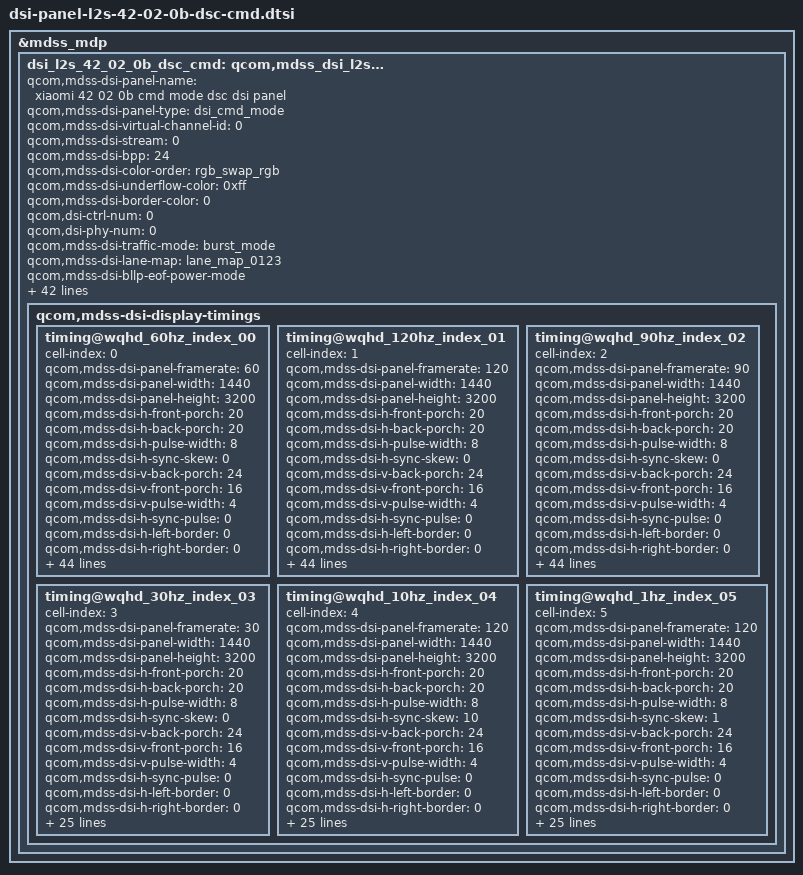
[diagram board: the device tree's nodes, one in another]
&mdss_mdp {
	dsi_l2s_42_02_0b_dsc_cmd: qcom,mdss_dsi_l2s_42_02_0b_dsc_cmd {
		qcom,mdss-dsi-panel-name = "xiaomi 42 02 0b cmd mode dsc dsi panel";
		qcom,mdss-dsi-panel-type = "dsi_cmd_mode";
		qcom,mdss-dsi-virtual-channel-id = <0>;
		qcom,mdss-dsi-stream = <0>;
		qcom,mdss-dsi-bpp = <24>;
		qcom,mdss-dsi-color-order = "rgb_swap_rgb";
		qcom,mdss-dsi-underflow-color = <0xff>;
		qcom,mdss-dsi-border-color = <0>;
		qcom,dsi-ctrl-num = <0>;
		qcom,dsi-phy-num = <0>;

		qcom,mdss-dsi-traffic-mode = "burst_mode";
		qcom,mdss-dsi-lane-map = "lane_map_0123";
		qcom,mdss-dsi-bllp-eof-power-mode;
		qcom,mdss-dsi-bllp-power-mode;
		qcom,mdss-dsi-lane-0-state;
		qcom,mdss-dsi-lane-1-state;
		qcom,mdss-dsi-lane-2-state;
		qcom,mdss-dsi-lane-3-state;
		qcom,mdss-dsi-dma-trigger = "trigger_sw";
		qcom,mdss-dsi-mdp-trigger = "none";
		qcom,mdss-dsi-reset-sequence = <0 10>, <1 10>;
		qcom,mdss-pan-physical-width-dimension = <701>;
		qcom,mdss-pan-physical-height-dimension = <1558>;
		qcom,mdss-dsi-te-pin-select = <1>;
		qcom,mdss-dsi-wr-mem-start = <0x2c>;
		qcom,mdss-dsi-wr-mem-continue = <0x3c>;
		qcom,mdss-dsi-te-dcs-command = <1>;
		qcom,mdss-dsi-te-check-enable;
		qcom,mdss-dsi-te-using-te-pin;
		qcom,mdss-dsi-tx-eot-append;
		qcom,mdss-dsi-lp11-init;

		qcom,mdss-dsi-bl-inverted-dbv;
		qcom,mdss-dsi-panel-dimming-enabled;
		qcom,bl-update-flag = "delay_until_first_frame";

		qcom,mdss-dsi-panel-hdr-enabled;
		qcom,mdss-dsi-panel-hdr-color-primaries = <14500 15500 32000
			17000 15500 30000 8000 3000>;
		qcom,mdss-dsi-panel-peak-brightness = <4200000>;
		qcom,mdss-dsi-panel-blackness-level = <3230>;

		qcom,mdss-dsi-dma-schedule-line = <1>;
		qcom,mdss-dsi-dma-schedule-window = <50>;

		/* IRQF_ONESHOT | IRQF_TRIGGER_HIGH */
		mi,esd-err-irq-gpio = <&tlmm 116 0x2004>;
		mi,panel-id = <0x004C3253 0x00420200>;

		mi,local-hbm-enabled;
		mi,local-hbm-alpha-ctrl-aa-area;

		mi,local-hbm-ui-ready-delay-num-frame = <4>; /* 4 frame */
		mi,fod-low-brightness-clone-threshold = <411>;
		mi,fod-low-brightness-lux-threshold = <1>;
		mi,need-fod-animal-in-normal-enabled;

		mi,panel-on-dimming-delay = <120>;
		mi,max-brightness-clone = <8191>;
		mi,normal-max-brightness-clone = <8191>;
		mi,thermal-dimming-flag;

		mi,doze-hbm-dbv-level = <229>;
		mi,doze-lbm-dbv-level = <16>;

		qcom,mdss-dsi-display-timings {
			timing@wqhd_60hz_index_00 {
				#include "dsi-panel-l2s-42-02-0b-dsc-cmd-common.dtsi"
				cell-index = <0>;
				qcom,mdss-dsi-panel-framerate = <60>;
				qcom,mdss-dsi-panel-width = <1440>;
				qcom,mdss-dsi-panel-height = <3200>;
				qcom,mdss-dsi-h-front-porch = <20>;
				qcom,mdss-dsi-h-back-porch = <20>;
				qcom,mdss-dsi-h-pulse-width = <8>;
				qcom,mdss-dsi-h-sync-skew = <0>;
				qcom,mdss-dsi-v-back-porch = <24>;
				qcom,mdss-dsi-v-front-porch = <16>;
				qcom,mdss-dsi-v-pulse-width = <4>;
				qcom,mdss-dsi-h-sync-pulse = <0>;
				qcom,mdss-dsi-h-left-border = <0>;
				qcom,mdss-dsi-h-right-border = <0>;
				qcom,mdss-dsi-v-top-border = <0>;
				qcom,mdss-dsi-v-bottom-border = <0>;
				qcom,mdss-dsi-panel-clockrate = <1240000000>;
				qcom,mdss-dsi-panel-jitter = <0x5 0x1>;
				qcom,mdss-mdp-transfer-time-us = <7300>;

				/* the cmd sequence sync TE */
				mi,mdss-dsi-exit-90fps-timing-switch-command = [
					39 00 00 40 00 00 02 5A 01
					39 00 00 40 00 00 06 F0 55 AA 52 08 00
					39 00 00 40 00 00 02 6F 1C
					39 00 00 40 00 00 09 BA 91 01 01 00 01 01 01 00
					39 00 00 40 00 00 02 BA 00
					39 00 00 00 00 00 02 2F 30
				];
				mi,mdss-dsi-exit-90fps-timing-switch-command-state = "dsi_hs_mode";

				qcom,mdss-dsi-timing-switch-command = [
					39 00 00 40 00 00 02 5A 01
					39 00 00 40 00 00 06 F0 55 AA 52 08 00
					39 00 00 40 00 00 02 6F 1C
					39 00 00 40 00 00 09 BA 91 01 01 00 01 01 01 00
					39 00 00 40 00 00 02 BA 00
					39 00 00 00 00 00 02 2F 30
				];
				qcom,mdss-dsi-timing-switch-command-state = "dsi_hs_mode";

				qcom,mdss-dsi-on-command = [
					/*DVDD strong*/
					39 00 00 40 00 00 06 F0 55 AA 52 08 01
					39 00 00 40 00 00 02 6F 01
					39 00 00 00 00 00 04 C5 0B 0B 0B
					/* source rising failing time */
					39 00 00 40 00 00 05 FF AA 55 A5 80
					39 00 00 40 00 00 02 6F 1B
					39 00 00 00 00 00 02 F4 55
					/* DSC setting */
					39 00 00 40 00 00 03 90 03 03
					39 00 00 00 00 00 13 91
					        89 28 00 28 D2 00 02 86 04 3A 00 0A 02 AB 01 E9
					        10 F0
					/* CASET/RASET */
					39 00 00 40 00 00 05 2A 00 00 05 9F
					39 00 00 00 00 00 05 2B 00 00 0C 7F
					/* TE ON */
					39 00 00 40 00 00 02 35 00
					39 00 00 40 00 00 05 3B 00 18 00 10
					39 00 00 00 00 00 02 5A 01
					/* BACKLIGHT ON */
					//DBV
					39 00 00 40 00 00 02 53 20
					39 00 00 40 00 00 07 51 00 00 00 00 00 00
					39 00 00 00 00 00 02 9C 01
					/*GIR OFF*/
					39 00 00 00 00 00 02 5F 01
					/* 60 Hz */
					39 00 00 40 00 00 02 5A 01
					39 00 00 40 00 00 06 F0 55 AA 52 08 00
					39 00 00 40 00 00 02 6F 1C
					39 00 00 40 00 00 09 BA 91 01 01 00 01 01 01 00
					39 00 00 40 00 00 02 BA 00
					39 00 00 00 00 00 02 2F 30
					/* round off */
					39 00 00 40 00 00 06 F0 55 AA 52 08 07
					39 00 00 00 00 00 02 C0 B0
					/*ESD Error flag  Active high*/
					39 00 00 40 00 00 06 F0 55 AA 52 08 00
					39 00 00 40 00 00 05 BE 47 CF 4C 4B
					39 00 00 40 00 00 02 6F 09
					39 00 00 00 00 00 02 BE 2A
					/*TP Hsync*/
					39 00 00 40 00 00 06 F0 55 AA 52 08 01
					39 00 00 00 00 00 07 D1 07 02 0C 00 00 0F
					/*spped flash reload*/
					//39 00 00 40 00 00 06 F0 55 AA 52 08 04
					//39 00 00 00 00 00 02 C2 12
					/* Sleep Out */
					05 00 00 00 78 00 01 11
					/*black mask off*/
					39 00 00 00 00 00 02 9B 00
					/* Display On */
					05 00 00 00 00 00 01 29
				];
				qcom,mdss-dsi-on-command-state = "dsi_lp_mode";

				mi,mdss-dsi-flat-mode-on-command = [
					39 00 00 40 00 00 02 2F 32
					39 00 00 00 00 00 02 5F 00
				];
				mi,mdss-dsi-flat-mode-on-command-state = "dsi_lp_mode";

				mi,mdss-dsi-flat-mode-off-command = [
					39 00 00 00 00 00 02 5F 01
				];
				mi,mdss-dsi-flat-mode-off-command-state = "dsi_lp_mode";

				qcom,mdss-dsi-nolp-command = [
					39 00 00 40 00 00 02 65 00
					39 00 00 40 00 00 02 38 00
					/*60HZ*/
					39 00 00 40 00 00 02 5A 01
					39 00 00 40 00 00 06 F0 55 AA 52 08 00
					39 00 00 40 00 00 02 6F 1C
					39 00 00 40 00 00 09 BA 91 01 01 00 01 01 01 00
					39 00 00 40 00 00 02 BA 00
					39 00 00 00 00 00 02 2F 30
				];
				qcom,mdss-dsi-nolp-command-state = "dsi_lp_mode";

				mi,mdss-dsi-doze-hbm-nolp-command = [
					39 00 00 40 00 00 02 65 00
					39 00 00 40 00 00 02 38 00
					/*60HZ*/
					39 00 00 40 00 00 02 5A 01
					39 00 00 40 00 00 06 F0 55 AA 52 08 00
					39 00 00 40 00 00 02 6F 1C
					39 00 00 40 00 00 09 BA 91 01 01 00 01 01 01 00
					39 00 00 40 00 00 02 BA 00
					39 00 00 00 00 00 02 2F 30
				];
				mi,mdss-dsi-doze-hbm-nolp-command-state = "dsi_lp_mode";

				mi,mdss-dsi-doze-lbm-nolp-command = [
					39 00 00 40 00 00 02 65 00
					39 00 00 40 00 00 02 38 00
					/*60HZ*/
					39 00 00 40 00 00 02 5A 01
					39 00 00 40 00 00 06 F0 55 AA 52 08 00
					39 00 00 40 00 00 02 6F 1C
					39 00 00 40 00 00 09 BA 91 01 01 00 01 01 01 00
					39 00 00 40 00 00 02 BA 00
					39 00 00 00 00 00 02 2F 30
				];
				mi,mdss-dsi-doze-lbm-nolp-command-state = "dsi_lp_mode";

				qcom,compression-mode = "dsc";
				qcom,mdss-dsc-version = <0x11>;
				qcom,mdss-dsc-scr-version = <0x0>;
				qcom,mdss-dsc-slice-height = <40>;
				qcom,mdss-dsc-slice-width = <720>;
				qcom,mdss-dsc-slice-per-pkt = <2>;
				qcom,mdss-dsc-bit-per-component = <8>;
				qcom,mdss-dsc-bit-per-pixel = <8>;
				qcom,mdss-dsc-block-prediction-enable;
			};

			timing@wqhd_120hz_index_01 {
				#include "dsi-panel-l2s-42-02-0b-dsc-cmd-common.dtsi"
				cell-index = <1>;
				qcom,mdss-dsi-panel-framerate = <120>;
				qcom,mdss-dsi-panel-width = <1440>;
				qcom,mdss-dsi-panel-height = <3200>;
				qcom,mdss-dsi-h-front-porch = <20>;
				qcom,mdss-dsi-h-back-porch = <20>;
				qcom,mdss-dsi-h-pulse-width = <8>;
				qcom,mdss-dsi-h-sync-skew = <0>;
				qcom,mdss-dsi-v-back-porch = <24>;
				qcom,mdss-dsi-v-front-porch = <16>;
				qcom,mdss-dsi-v-pulse-width = <4>;
				qcom,mdss-dsi-h-sync-pulse = <0>;
				qcom,mdss-dsi-h-left-border = <0>;
				qcom,mdss-dsi-h-right-border = <0>;
				qcom,mdss-dsi-v-top-border = <0>;
				qcom,mdss-dsi-v-bottom-border = <0>;
				qcom,mdss-dsi-panel-clockrate = <1240000000>;
				qcom,mdss-dsi-panel-jitter = <0x5 0x1>;
				qcom,mdss-mdp-transfer-time-us = <7300>;

				/* the cmd sequence sync TE */
				mi,mdss-dsi-exit-90fps-timing-switch-command = [
					39 00 00 00 00 00 02 2F 00
				];
				mi,mdss-dsi-exit-90fps-timing-switch-command-state = "dsi_hs_mode";

				qcom,mdss-dsi-timing-switch-command = [
					39 00 00 00 00 00 02 2F 00
				];
				qcom,mdss-dsi-timing-switch-command-state = "dsi_hs_mode";

				qcom,mdss-dsi-on-command = [
					/*DVDD strong*/
					39 00 00 40 00 00 06 F0 55 AA 52 08 01
					39 00 00 40 00 00 02 6F 01
					39 00 00 00 00 00 04 C5 0B 0B 0B
					/* source rising failing time */
					39 00 00 40 00 00 05 FF AA 55 A5 80
					39 00 00 40 00 00 02 6F 1B
					39 00 00 00 00 00 02 F4 55
					/* DSC setting */
					39 00 00 40 00 00 03 90 03 03
					39 00 00 00 00 00 13 91
					        89 28 00 28 D2 00 02 86 04 3A 00 0A 02 AB 01 E9
					        10 F0
					/* CASET/RASET */
					39 00 00 40 00 00 05 2A 00 00 05 9F
					39 00 00 00 00 00 05 2B 00 00 0C 7F
					/* TE ON */
					39 00 00 40 00 00 02 35 00
					39 00 00 40 00 00 05 3B 00 18 00 10
					39 00 00 00 00 00 02 5A 01
					/* BACKLIGHT ON */
					//DBV
					39 00 00 40 00 00 02 53 20
					39 00 00 40 00 00 07 51 00 00 00 00 00 00
					39 00 00 00 00 00 02 9C 01
					/*GIR OFF*/
					39 00 00 00 00 00 02 5F 01
					/* 120 Hz */
					39 00 00 40 00 00 02 2F 00
					39 00 00 00 00 00 02 26 00
					/* round off */
					39 00 00 00 00 00 06 F0 55 AA 52 08 07
					39 00 00 00 00 00 02 C0 B0
					/*ESD Error flag  Active high*/
					39 00 00 40 00 00 06 F0 55 AA 52 08 00
					39 00 00 40 00 00 05 BE 47 CF 4C 4B
					39 00 00 40 00 00 02 6F 09
					39 00 00 00 00 00 02 BE 2A
					/*TP Hsync*/
					39 00 00 40 00 00 06 F0 55 AA 52 08 01
					39 00 00 00 00 00 07 D1 07 02 0C 00 00 0F
					/* Sleep Out */
					05 00 00 00 78 00 01 11
					/* Display On */
					05 00 00 00 00 00 01 29
				];
				qcom,mdss-dsi-on-command-state = "dsi_lp_mode";

				mi,mdss-dsi-flat-mode-on-command = [
					39 00 00 00 00 00 02 2F 02
				];
				mi,mdss-dsi-flat-mode-on-command-state = "dsi_lp_mode";

				mi,mdss-dsi-flat-mode-off-command = [
					39 00 00 40 00 00 02 2F 00
					39 00 00 00 00 00 02 26 00
				];
				mi,mdss-dsi-flat-mode-off-command-state = "dsi_lp_mode";

				qcom,mdss-dsi-nolp-command = [
					39 00 00 40 00 00 02 65 00
					39 00 00 40 00 00 02 38 00
					/*120HZ*/
					39 00 00 00 00 00 02 2F 00
				];
				qcom,mdss-dsi-nolp-command-state = "dsi_lp_mode";

				mi,mdss-dsi-doze-hbm-nolp-command = [
					39 00 00 40 00 00 02 65 00
					39 00 00 40 00 00 02 38 00
					/*120HZ*/
					39 00 00 00 00 00 02 2F 00
				];
				mi,mdss-dsi-doze-hbm-nolp-command-state = "dsi_lp_mode";

				mi,mdss-dsi-doze-lbm-nolp-command = [
					39 00 00 40 00 00 02 65 00
					39 00 00 40 00 00 02 38 00
					/*120HZ*/
					39 00 00 00 00 00 02 2F 00
				];
				mi,mdss-dsi-doze-lbm-nolp-command-state = "dsi_lp_mode";

				qcom,compression-mode = "dsc";
				qcom,mdss-dsc-version = <0x11>;
				qcom,mdss-dsc-scr-version = <0x0>;
				qcom,mdss-dsc-slice-height = <40>;
				qcom,mdss-dsc-slice-width = <720>;
				qcom,mdss-dsc-slice-per-pkt = <2>;
				qcom,mdss-dsc-bit-per-component = <8>;
				qcom,mdss-dsc-bit-per-pixel = <8>;
				qcom,mdss-dsc-block-prediction-enable;
			};

			timing@wqhd_90hz_index_02 {
				#include "dsi-panel-l2s-42-02-0b-dsc-cmd-common.dtsi"
				cell-index = <2>;
				qcom,mdss-dsi-panel-framerate = <90>;
				qcom,mdss-dsi-panel-width = <1440>;
				qcom,mdss-dsi-panel-height = <3200>;
				qcom,mdss-dsi-h-front-porch = <20>;
				qcom,mdss-dsi-h-back-porch = <20>;
				qcom,mdss-dsi-h-pulse-width = <8>;
				qcom,mdss-dsi-h-sync-skew = <0>;
				qcom,mdss-dsi-v-back-porch = <24>;
				qcom,mdss-dsi-v-front-porch = <16>;
				qcom,mdss-dsi-v-pulse-width = <4>;
				qcom,mdss-dsi-h-sync-pulse = <0>;
				qcom,mdss-dsi-h-left-border = <0>;
				qcom,mdss-dsi-h-right-border = <0>;
				qcom,mdss-dsi-v-top-border = <0>;
				qcom,mdss-dsi-v-bottom-border = <0>;
				qcom,mdss-dsi-panel-clockrate = <1240000000>;
				qcom,mdss-dsi-panel-jitter = <0x5 0x1>;
				qcom,mdss-mdp-transfer-time-us = <7300>;

				mi,mdss-dsi-exit-90fps-timing-switch-command = [
					39 00 00 00 00 00 02 2F 01
				];
				mi,mdss-dsi-exit-90fps-timing-switch-command-state = "dsi_hs_mode";

				qcom,mdss-dsi-timing-switch-command = [
					39 00 00 00 00 00 02 2F 01
				];
				qcom,mdss-dsi-timing-switch-command-state = "dsi_hs_mode";

				qcom,mdss-dsi-on-command = [
					/*DVDD strong*/
					39 00 00 40 00 00 06 F0 55 AA 52 08 01
					39 00 00 40 00 00 02 6F 01
					39 00 00 00 00 00 04 C5 0B 0B 0B
					/* source rising failing time */
					39 00 00 40 00 00 05 FF AA 55 A5 80
					39 00 00 40 00 00 02 6F 1B
					39 00 00 00 00 00 02 F4 55
					/* DSC setting */
					39 00 00 40 00 00 03 90 03 03
					39 00 00 00 00 00 13 91
						89 28 00 28 D2 00 02 86 04 3A 00 0A 02 AB 01 E9
						10 F0
					/* CASET/RASET */
					39 00 00 40 00 00 05 2A 00 00 05 9F
					39 00 00 00 00 00 05 2B 00 00 0C 7F
					/* TE ON */
					39 00 00 40 00 00 02 35 00
					39 00 00 40 00 00 05 3B 00 18 00 10
					39 00 00 00 00 00 02 5A 01
					//DBV
					39 00 00 40 00 00 02 53 20
					39 00 00 40 00 00 07 51 00 00 00 00 00 00
					39 00 00 00 00 00 02 9C 01
					/*GIR OFF*/
					39 00 00 00 00 00 02 5F 01
					/* 90 Hz */
					39 00 00 00 00 00 02 2F 01
					/* round off */
					39 00 00 40 00 00 06 F0 55 AA 52 08 07
					39 00 00 00 00 00 02 C0 B0
					/*ESD Error flag  Active high*/
					39 00 00 40 00 00 06 F0 55 AA 52 08 00
					39 00 00 40 00 00 05 BE 47 CF 4C 4B
					39 00 00 40 00 00 02 6F 09
					39 00 00 00 00 00 02 BE 2A
					/*TP Hsync*/
					39 00 00 40 00 00 06 F0 55 AA 52 08 01
					39 00 00 00 00 00 07 D1 07 02 0C 00 00 0F
					/* Sleep Out */
					05 00 00 00 78 00 01 11
					/* Display On */
					05 00 00 00 00 00 01 29
				];
				qcom,mdss-dsi-on-command-state = "dsi_lp_mode";

				mi,mdss-dsi-flat-mode-on-command = [
					39 00 00 00 00 00 02 2F 03
				];
				mi,mdss-dsi-flat-mode-on-command-state = "dsi_lp_mode";

				mi,mdss-dsi-flat-mode-off-command = [
					39 00 00 00 00 00 02 2F 01
				];
                                mi,mdss-dsi-flat-mode-off-command-state = "dsi_lp_mode";

				qcom,mdss-dsi-nolp-command = [
					39 00 00 40 00 00 02 65 00
					39 00 00 40 00 00 02 38 00
					/*90HZ*/
					39 00 00 00 00 00 02 2F 01
				];
				qcom,mdss-dsi-nolp-command-state = "dsi_lp_mode";

				mi,mdss-dsi-doze-hbm-nolp-command = [
					39 00 00 40 00 00 03 51 07 FF
					39 00 00 40 00 00 02 65 00
					39 00 00 40 00 00 02 38 00
					/*90HZ*/
					39 00 00 00 00 00 02 2F 01
				];
				mi,mdss-dsi-doze-hbm-nolp-command-state = "dsi_lp_mode";

				mi,mdss-dsi-doze-lbm-nolp-command = [
					39 00 00 40 00 00 03 51 07 FF
					39 00 00 40 00 00 02 65 00
					39 00 00 40 00 00 02 38 00
					/*90HZ*/
					39 00 00 00 00 00 02 2F 01
				];
				mi,mdss-dsi-doze-lbm-nolp-command-state = "dsi_lp_mode";

				qcom,compression-mode = "dsc";
				qcom,mdss-dsc-version = <0x11>;
				qcom,mdss-dsc-scr-version = <0x0>;
				qcom,mdss-dsc-slice-height = <40>;
				qcom,mdss-dsc-slice-width = <720>;
				qcom,mdss-dsc-slice-per-pkt = <2>;
				qcom,mdss-dsc-bit-per-component = <8>;
				qcom,mdss-dsc-bit-per-pixel = <8>;
				qcom,mdss-dsc-block-prediction-enable;
			};

			timing@wqhd_30hz_index_03 {
				#include "dsi-panel-l2s-42-02-0b-dsc-cmd-common.dtsi"
				cell-index = <3>;
				qcom,mdss-dsi-panel-framerate = <30>;
				qcom,mdss-dsi-panel-width = <1440>;
				qcom,mdss-dsi-panel-height = <3200>;
				qcom,mdss-dsi-h-front-porch = <20>;
				qcom,mdss-dsi-h-back-porch = <20>;
				qcom,mdss-dsi-h-pulse-width = <8>;
				qcom,mdss-dsi-h-sync-skew = <0>;
				qcom,mdss-dsi-v-back-porch = <24>;
				qcom,mdss-dsi-v-front-porch = <16>;
				qcom,mdss-dsi-v-pulse-width = <4>;
				qcom,mdss-dsi-h-sync-pulse = <0>;
				qcom,mdss-dsi-h-left-border = <0>;
				qcom,mdss-dsi-h-right-border = <0>;
				qcom,mdss-dsi-v-top-border = <0>;
				qcom,mdss-dsi-v-bottom-border = <0>;
				qcom,mdss-dsi-panel-clockrate = <1240000000>;
				qcom,mdss-dsi-panel-jitter = <0x5 0x1>;
				qcom,mdss-mdp-transfer-time-us = <7300>;

				/* the cmd sequence sync TE */
				mi,mdss-dsi-exit-90fps-timing-switch-command = [
					39 00 00 40 00 00 02 5A 01
					39 00 00 40 00 00 06 F0 55 AA 52 08 00
					39 00 00 40 00 00 02 6F 1C
					39 00 00 40 00 00 09 BA 91 03 03 00 01 03 03 00
					39 00 00 40 00 00 02 BA 00
					39 00 00 00 00 00 02 2F 30
				];
				mi,mdss-dsi-exit-90fps-timing-switch-command-state = "dsi_hs_mode";

				qcom,mdss-dsi-timing-switch-command = [
					39 00 00 40 00 00 02 5A 01
					39 00 00 40 00 00 06 F0 55 AA 52 08 00
					39 00 00 40 00 00 02 6F 1C
					39 00 00 40 00 00 09 BA 91 03 03 00 01 03 03 00
					39 00 00 40 00 00 02 BA 00
					39 00 00 00 00 00 02 2F 30
				];
				qcom,mdss-dsi-timing-switch-command-state = "dsi_hs_mode";

				qcom,mdss-dsi-on-command = [
					/*DVDD strong*/
					39 00 00 40 00 00 06 F0 55 AA 52 08 01
					39 00 00 40 00 00 02 6F 01
					39 00 00 00 00 00 04 C5 0B 0B 0B
					/* source rising failing time */
					39 00 00 40 00 00 05 FF AA 55 A5 80
					39 00 00 40 00 00 02 6F 1B
					39 00 00 00 00 00 02 F4 55
					/* DSC setting */
					39 00 00 40 00 00 03 90 03 03
					39 00 00 00 00 00 13 91
					        89 28 00 28 D2 00 02 86 04 3A 00 0A 02 AB 01 E9
					        10 F0
					/* CASET/RASET */
					39 00 00 40 00 00 05 2A 00 00 05 9F
					39 00 00 00 00 00 05 2B 00 00 0C 7F
					/* TE ON */
					39 00 00 40 00 00 02 35 00
					39 00 00 40 00 00 05 3B 00 18 00 10
					39 00 00 00 00 00 02 5A 01
					/* BACKLIGHT ON */
					//DBV
					39 00 00 40 00 00 02 53 20
					39 00 00 40 00 00 07 51 00 00 00 00 00 00
					39 00 00 00 00 00 02 9C 01
					/*GIR OFF*/
					39 00 00 00 00 00 02 5F 01
					/* 30 Hz */
					39 00 00 40 00 00 02 5A 01
					39 00 00 40 00 00 06 F0 55 AA 52 08 00
					39 00 00 40 00 00 02 6F 1C
					39 00 00 40 00 00 09 BA 91 03 03 00 01 03 03 00
					39 00 00 40 00 00 02 BA 00
					39 00 00 00 00 00 02 2F 30
					/* round off */
					39 00 00 40 00 00 06 F0 55 AA 52 08 07
					39 00 00 00 00 00 02 C0 B0
					/*ESD Error flag  Active high*/
					39 00 00 40 00 00 06 F0 55 AA 52 08 00
					39 00 00 40 00 00 05 BE 47 CF 4C 4B
					39 00 00 40 00 00 02 6F 09
					39 00 00 00 00 00 02 BE 2A
					/*TP Hsync*/
					39 00 00 40 00 00 06 F0 55 AA 52 08 01
					39 00 00 00 00 00 07 D1 07 02 0C 00 00 0F
					/* Sleep Out */
					05 00 00 00 78 00 01 11
					/* Display On */
					05 00 00 00 00 00 01 29
				];
				qcom,mdss-dsi-on-command-state = "dsi_lp_mode";

				qcom,compression-mode = "dsc";
				qcom,mdss-dsc-version = <0x11>;
				qcom,mdss-dsc-scr-version = <0x0>;
				qcom,mdss-dsc-slice-height = <40>;
				qcom,mdss-dsc-slice-width = <720>;
				qcom,mdss-dsc-slice-per-pkt = <2>;
				qcom,mdss-dsc-bit-per-component = <8>;
				qcom,mdss-dsc-bit-per-pixel = <8>;
				qcom,mdss-dsc-block-prediction-enable;
			};


			timing@wqhd_10hz_index_04 {
				#include "dsi-panel-l2s-42-02-0b-dsc-cmd-common.dtsi"
				cell-index = <4>;
				qcom,mdss-dsi-panel-framerate = <120>;
				qcom,mdss-dsi-panel-width = <1440>;
				qcom,mdss-dsi-panel-height = <3200>;
				qcom,mdss-dsi-h-front-porch = <20>;
				qcom,mdss-dsi-h-back-porch = <20>;
				qcom,mdss-dsi-h-pulse-width = <8>;
				qcom,mdss-dsi-h-sync-skew = <10>;
				qcom,mdss-dsi-v-back-porch = <24>;
				qcom,mdss-dsi-v-front-porch = <16>;
				qcom,mdss-dsi-v-pulse-width = <4>;
				qcom,mdss-dsi-h-sync-pulse = <0>;
				qcom,mdss-dsi-h-left-border = <0>;
				qcom,mdss-dsi-h-right-border = <0>;
				qcom,mdss-dsi-v-top-border = <0>;
				qcom,mdss-dsi-v-bottom-border = <0>;
				qcom,mdss-dsi-panel-clockrate = <1240000000>;
				qcom,mdss-dsi-panel-jitter = <0x5 0x1>;
				qcom,mdss-mdp-transfer-time-us = <7300>;

				/* the cmd sequence sync TE */
				mi,mdss-dsi-exit-90fps-timing-switch-command = [
					39 00 00 40 00 00 02 5A 00
					39 00 00 40 00 00 06 F0 55 AA 52 08 00
					39 00 00 40 00 00 02 6F 1C
					39 00 00 40 00 00 09 BA 91 0B 0B 00 01 0B 0B 00
					39 00 00 40 00 00 02 BA 00
					39 00 00 00 00 00 02 2F 30
				];
				mi,mdss-dsi-exit-90fps-timing-switch-command-state = "dsi_hs_mode";

				qcom,mdss-dsi-timing-switch-command = [
					39 00 00 40 00 00 02 5A 00
					39 00 00 40 00 00 06 F0 55 AA 52 08 00
					39 00 00 40 00 00 02 6F 1C
					39 00 00 40 00 00 09 BA 91 0B 0B 00 01 0B 0B 00
					39 00 00 40 00 00 02 BA 00
					39 00 00 00 00 00 02 2F 30
				];
				qcom,mdss-dsi-timing-switch-command-state = "dsi_hs_mode";

				qcom,mdss-dsi-on-command = [
					/*DVDD strong*/
					39 00 00 40 00 00 06 F0 55 AA 52 08 01
					39 00 00 40 00 00 02 6F 01
					39 00 00 00 00 00 04 C5 0B 0B 0B
					/* source rising failing time */
					39 00 00 40 00 00 05 FF AA 55 A5 80
					39 00 00 40 00 00 02 6F 1B
					39 00 00 00 00 00 02 F4 55
					/* DSC setting */
					39 00 00 40 00 00 03 90 03 03
					39 00 00 00 00 00 13 91
					        89 28 00 28 D2 00 02 86 04 3A 00 0A 02 AB 01 E9
					        10 F0
					/* CASET/RASET */
					39 00 00 40 00 00 05 2A 00 00 05 9F
					39 00 00 00 00 00 05 2B 00 00 0C 7F
					/* TE ON */
					39 00 00 40 00 00 02 35 00
					39 00 00 40 00 00 05 3B 00 18 00 10
					39 00 00 00 00 00 02 5A 01
					/* BACKLIGHT ON */
					//DBV
					39 00 00 40 00 00 02 53 20
					39 00 00 40 00 00 07 51 00 00 00 00 00 00
					39 00 00 00 00 00 02 9C 01
					/*GIR OFF*/
					39 00 00 00 00 00 02 5F 01
					/* 10 Hz */
					39 00 00 40 00 00 02 5A 00
					39 00 00 40 00 00 06 F0 55 AA 52 08 00
					39 00 00 40 00 00 02 6F 1C
					39 00 00 40 00 00 09 BA 91 0B 0B 00 01 0B 0B 00
					39 00 00 40 00 00 02 BA 00
					39 00 00 00 00 00 02 2F 30
					/* round off */
					39 00 00 40 00 00 06 F0 55 AA 52 08 07
					39 00 00 00 00 00 02 C0 B0	
					/*ESD Error flag  Active high*/
					39 00 00 40 00 00 06 F0 55 AA 52 08 00
					39 00 00 40 00 00 05 BE 47 CF 4C 4B
					39 00 00 40 00 00 02 6F 09
					39 00 00 00 00 00 02 BE 2A
					/*TP Hsync*/
					39 00 00 40 00 00 06 F0 55 AA 52 08 01
					39 00 00 00 00 00 07 D1 07 02 0C 00 00 0F
					/* Sleep Out */
					05 00 00 00 78 00 01 11
					/* Display On */
					05 00 00 00 00 00 01 29
				];
				qcom,mdss-dsi-on-command-state = "dsi_lp_mode";

				qcom,compression-mode = "dsc";
				qcom,mdss-dsc-version = <0x11>;
				qcom,mdss-dsc-scr-version = <0x0>;
				qcom,mdss-dsc-slice-height = <40>;
				qcom,mdss-dsc-slice-width = <720>;
				qcom,mdss-dsc-slice-per-pkt = <2>;
				qcom,mdss-dsc-bit-per-component = <8>;
				qcom,mdss-dsc-bit-per-pixel = <8>;
				qcom,mdss-dsc-block-prediction-enable;
			};

			timing@wqhd_1hz_index_05 {
				#include "dsi-panel-l2s-42-02-0b-dsc-cmd-common.dtsi"
				cell-index = <5>;
				qcom,mdss-dsi-panel-framerate = <120>;
				qcom,mdss-dsi-panel-width = <1440>;
				qcom,mdss-dsi-panel-height = <3200>;
				qcom,mdss-dsi-h-front-porch = <20>;
				qcom,mdss-dsi-h-back-porch = <20>;
				qcom,mdss-dsi-h-pulse-width = <8>;
				qcom,mdss-dsi-h-sync-skew = <1>;
				qcom,mdss-dsi-v-back-porch = <24>;
				qcom,mdss-dsi-v-front-porch = <16>;
				qcom,mdss-dsi-v-pulse-width = <4>;
				qcom,mdss-dsi-h-sync-pulse = <0>;
				qcom,mdss-dsi-h-left-border = <0>;
				qcom,mdss-dsi-h-right-border = <0>;
				qcom,mdss-dsi-v-top-border = <0>;
				qcom,mdss-dsi-v-bottom-border = <0>;
				qcom,mdss-dsi-panel-clockrate = <1240000000>;
				qcom,mdss-dsi-panel-jitter = <0x5 0x1>;
				qcom,mdss-mdp-transfer-time-us = <7300>;

				/* the cmd sequence sync TE */
				mi,mdss-dsi-exit-90fps-timing-switch-command = [
					39 00 00 40 00 00 02 5A 00
					39 00 00 40 00 00 06 F0 55 AA 52 08 00
					39 00 00 40 00 00 02 6F 1C
					39 00 00 40 00 00 09 BA 91 77 77 00 01 77 77 00
					39 00 00 40 00 00 02 BA 00
					39 00 00 00 00 00 02 2F 30
				];
				mi,mdss-dsi-exit-90fps-timing-switch-command-state = "dsi_hs_mode";

				qcom,mdss-dsi-timing-switch-command = [
					39 00 00 40 00 00 02 5A 00
					39 00 00 40 00 00 06 F0 55 AA 52 08 00
					39 00 00 40 00 00 02 6F 1C
					39 00 00 40 00 00 09 BA 91 77 77 00 01 77 77 00
					39 00 00 40 00 00 02 BA 00
					39 00 00 00 00 00 02 2F 30
				];
				qcom,mdss-dsi-timing-switch-command-state = "dsi_hs_mode";

				qcom,mdss-dsi-on-command = [
					/*DVDD strong*/
					39 00 00 40 00 00 06 F0 55 AA 52 08 01
					39 00 00 40 00 00 02 6F 01
					39 00 00 00 00 00 04 C5 0B 0B 0B
					/* source rising failing time */
					39 00 00 40 00 00 05 FF AA 55 A5 80
					39 00 00 40 00 00 02 6F 1B
					39 00 00 00 00 00 02 F4 55
					/* DSC setting */
					39 00 00 40 00 00 03 90 03 03
					39 00 00 00 00 00 13 91
					        89 28 00 28 D2 00 02 86 04 3A 00 0A 02 AB 01 E9
					        10 F0
					/* CASET/RASET */
					39 00 00 40 00 00 05 2A 00 00 05 9F
					39 00 00 00 00 00 05 2B 00 00 0C 7F
					/* TE ON */
					39 00 00 40 00 00 02 35 00
					39 00 00 40 00 00 05 3B 00 18 00 10
					39 00 00 00 00 00 02 5A 01
					/* BACKLIGHT ON */
					//DBV
					39 00 00 40 00 00 02 53 20
					39 00 00 40 00 00 07 51 00 00 00 00 00 00
					39 00 00 00 00 00 02 9C 01
					/*GIR OFF*/
					39 00 00 00 00 00 02 5F 01
					/* 1 Hz */
					39 00 00 40 00 00 02 5A 00
					39 00 00 40 00 00 06 F0 55 AA 52 08 00
					39 00 00 40 00 00 02 6F 1C
					39 00 00 40 00 00 09 BA 91 77 77 00 01 77 77 00
					39 00 00 40 00 00 02 BA 00
					39 00 00 00 00 00 02 2F 30
					/* round off */
					39 00 00 40 00 00 06 F0 55 AA 52 08 07
					39 00 00 00 00 00 02 C0 B0
					/*ESD Error flag  Active high*/
					39 00 00 40 00 00 06 F0 55 AA 52 08 00
					39 00 00 40 00 00 05 BE 47 CF 4C 4B
					39 00 00 40 00 00 02 6F 09
					39 00 00 00 00 00 02 BE 2A
					/*TP Hsync*/
					39 00 00 40 00 00 06 F0 55 AA 52 08 01
					39 00 00 00 00 00 07 D1 07 02 0C 00 00 0F
					/* Sleep Out */
					05 00 00 00 78 00 01 11
					/* Display On */
					05 00 00 00 00 00 01 29
				];
				qcom,mdss-dsi-on-command-state = "dsi_lp_mode";

				qcom,compression-mode = "dsc";
				qcom,mdss-dsc-version = <0x11>;
				qcom,mdss-dsc-scr-version = <0x0>;
				qcom,mdss-dsc-slice-height = <40>;
				qcom,mdss-dsc-slice-width = <720>;
				qcom,mdss-dsc-slice-per-pkt = <2>;
				qcom,mdss-dsc-bit-per-component = <8>;
				qcom,mdss-dsc-bit-per-pixel = <8>;
				qcom,mdss-dsc-block-prediction-enable;
			};
		};
	};
};
